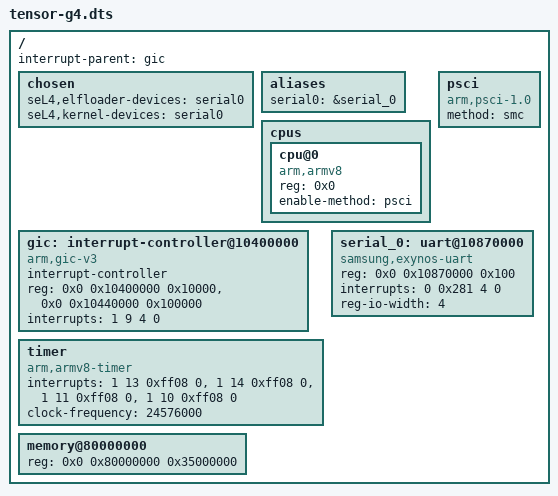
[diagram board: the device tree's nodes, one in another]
/dts-v1/;

/ {
    #address-cells = <2>;
    #size-cells = <1>;
    interrupt-parent = <&gic>;      /* label ref -- dtc resolves */

    chosen {
        seL4,elfloader-devices = "serial0";
        seL4,kernel-devices = "serial0";
    };

    aliases { serial0 = &serial_0; };   /* label ref, not string path */

    cpus {
        #address-cells = <1>;
        #size-cells = <0>;
        cpu@0 {
            device_type = "cpu";
            compatible = "arm,armv8";
            reg = <0x0>;
            enable-method = "psci";
        };
    };

    psci {
        compatible = "arm,psci-1.0";
        method = "smc";
    };

    gic: interrupt-controller@10400000 {
    	compatible = "arm,gic-v3";
    	#interrupt-cells = <4>;
    	#address-cells = <2>;
    	#size-cells = <1>;
    	interrupt-controller;
    	reg = <0x0 0x10400000 0x10000>,     /* GICD */
              <0x0 0x10440000 0x100000>;    /* GICR -- match rule's kernel_size */
    	interrupts = <1 9 4 0>;
    };


    timer {
        compatible = "arm,armv8-timer";
        interrupts = <1 13 0xff08 0>,
                     <1 14 0xff08 0>,
                     <1 11 0xff08 0>,
                     <1 10 0xff08 0>;
        clock-frequency = <24576000>;
    };

    serial_0: uart@10870000 {
        compatible = "samsung,exynos-uart";
        reg = <0x0 0x10870000 0x100>;
        interrupts = <0 0x281 4 0>;
        reg-io-width = <4>;
    };

    memory@80000000 {
        device_type = "memory";
        reg = <0x0 0x80000000 0x35000000>;
    };
};
